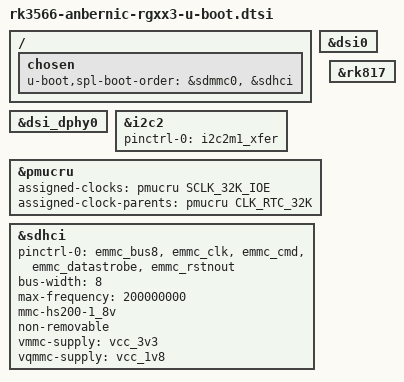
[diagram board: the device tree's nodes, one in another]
// SPDX-License-Identifier: (GPL-2.0+ OR MIT)

#include "rk356x-u-boot.dtsi"

/ {
	chosen {
		u-boot,spl-boot-order = &sdmmc0, &sdhci;
	};
};

&dsi_dphy0 {
	status = "okay";
};

&dsi0 {
	status = "okay";
};

&i2c2 {
	pinctrl-0 = <&i2c2m1_xfer>;
	pinctrl-names = "default";
	status = "okay";
};

&pmucru {
	assigned-clocks = <&pmucru SCLK_32K_IOE>;
	assigned-clock-parents = <&pmucru CLK_RTC_32K>;
};

/*
 * We don't need the clocks, but if they are present they may cause
 * probing to fail so we remove them for U-Boot.
 */
&rk817 {
	/delete-property/ assigned-clocks;
	/delete-property/ assigned-clock-parents;
	/delete-property/ clocks;
	/delete-property/ clock-names;
};

&sdhci {
	pinctrl-0 = <&emmc_bus8>, <&emmc_clk>, <&emmc_cmd>,
		    <&emmc_datastrobe>, <&emmc_rstnout>;
	pinctrl-names = "default";
	bus-width = <8>;
	max-frequency = <200000000>;
	mmc-hs200-1_8v;
	non-removable;
	vmmc-supply = <&vcc_3v3>;
	vqmmc-supply = <&vcc_1v8>;
	status = "okay";
};
